# CY8C5888LTI_LP097 register map
File version: 0.1
CY8C58LP
Registers are 8-bit, read-write, no defined reset value unless marked. A register's access mark holds for its fields unless they carry their own. Offsets are from the block's base; lines under a group give offsets from that group; [hi:lo] are bit positions; {n}, {i} and the like mark numbered series; 'fields as' and 'values as' point back to an identical list; <NAME> marks a mode.

## Memory map
0x00000000 SLM_TRIG
0x00000000 BLANKING_DELAY
0x00000000 CAM_SEL_REG
0x00000000 ACTIVATE_SLM
0x00000000 BLANK_TOGGLE
0x00000000 TRIG_CNT_RST
0x00000000 USBUART — USBFS
0x00000000 TRG_CNT
0x00000000 STAGE_REG
0x00000000 STAGE_TRIG
0x00000000 SLM_WAIT
0x00000000 ENBL_TRIG_ISR

## SLM_TRIG
Base 0x00000000
0x40006408 SLM_TRIG_COUNTER 32-bit — UDB.A0 - Current Counter Value
0x40006428 SLM_TRIG_PERIOD 32-bit — UDB.D0 - Assigned Period
0x40006438 SLM_TRIG_COMPARE 32-bit — UDB.D1 - Assigned Compare Value
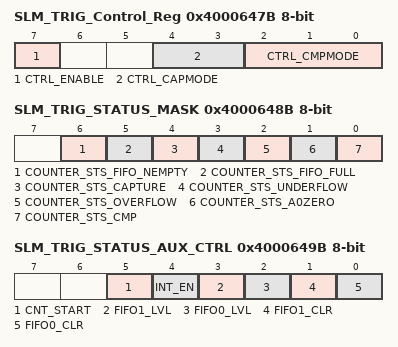
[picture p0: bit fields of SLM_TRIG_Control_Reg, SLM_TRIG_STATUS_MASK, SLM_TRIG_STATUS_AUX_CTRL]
0x4000647B SLM_TRIG_Control_Reg — UDB Control Register - Assigned Control Register Value
  [7] CTRL_ENABLE — Enable Counter
  [4:3] CTRL_CAPMODE — Capture mode
  [2:0] CTRL_CMPMODE — Compare mode
0x4000648B SLM_TRIG_STATUS_MASK — UDB Status bits Interrupt Mask Enable Register
  [6] COUNTER_STS_FIFO_NEMPTY — FIFO Not Empty Status
  [5] COUNTER_STS_FIFO_FULL — FIFO Full Status
  [4] COUNTER_STS_CAPTURE — Capture Status
  [3] COUNTER_STS_UNDERFLOW — Underflow status
  [2] COUNTER_STS_OVERFLOW — Overflow status
  [1] COUNTER_STS_A0ZERO — A0 Zero ouput status
  [0] COUNTER_STS_CMP — Compare output status
0x4000649B SLM_TRIG_STATUS_AUX_CTRL — UDB Auxilliary Control Register
  [5] CNT_START — FIFO0 clear
    0=E_CNT_START0 (Disable counter); 1=E_CNT_START1 (Enable counter)
  [4] INT_EN
    0=E_INT_EN0 (Interrupt disabled); 1=E_INT_EN1 (Interrupt enabled)
  [3] FIFO1_LVL — FIFO level
    0=E_FIFO_LVL_0 (FIFO LVL: input mode: FIFO not full; output mode: FIFO not empty); 1=E_FIFO_LVL_1 (FIFO LVL: input mode: FIFO at least 1/2 empty; output mode: FIFO at least 1/2 full)
  [2] FIFO0_LVL — FIFO level
    values as FIFO1_LVL
  [1] FIFO1_CLR — FIFO1 clear
    0=E_FIFO_CLR_0 (Normal FIFO operation); 1=E_FIFO_CLR_1 (Clear FIFO state)
  [0] FIFO0_CLR — FIFO0 clear
    values as FIFO1_CLR

## BLANKING_DELAY
Base 0x00000000
0x40006402 BLANKING_DELAY_COUNTER 32-bit — UDB.A0 - Current Counter Value
0x40006422 BLANKING_DELAY_PERIOD 32-bit — UDB.D0 - Assigned Period
0x40006432 BLANKING_DELAY_COMPARE 32-bit — UDB.D1 - Assigned Compare Value
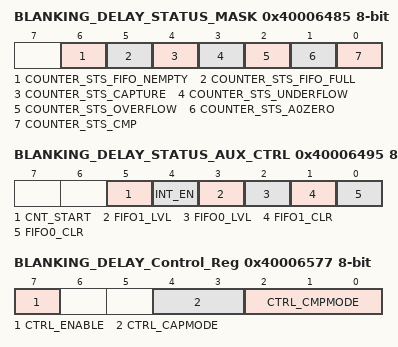
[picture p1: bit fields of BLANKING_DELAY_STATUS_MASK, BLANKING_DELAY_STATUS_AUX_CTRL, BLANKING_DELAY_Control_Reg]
0x40006485 BLANKING_DELAY_STATUS_MASK — UDB Status bits Interrupt Mask Enable Register
  [6] COUNTER_STS_FIFO_NEMPTY — FIFO Not Empty Status
  [5] COUNTER_STS_FIFO_FULL — FIFO Full Status
  [4] COUNTER_STS_CAPTURE — Capture Status
  [3] COUNTER_STS_UNDERFLOW — Underflow status
  [2] COUNTER_STS_OVERFLOW — Overflow status
  [1] COUNTER_STS_A0ZERO — A0 Zero ouput status
  [0] COUNTER_STS_CMP — Compare output status
0x40006495 BLANKING_DELAY_STATUS_AUX_CTRL — UDB Auxilliary Control Register
  [5] CNT_START — FIFO0 clear
    0=E_CNT_START0 (Disable counter); 1=E_CNT_START1 (Enable counter)
  [4] INT_EN
    0=E_INT_EN0 (Interrupt disabled); 1=E_INT_EN1 (Interrupt enabled)
  [3] FIFO1_LVL — FIFO level
    0=E_FIFO_LVL_0 (FIFO LVL: input mode: FIFO not full; output mode: FIFO not empty); 1=E_FIFO_LVL_1 (FIFO LVL: input mode: FIFO at least 1/2 empty; output mode: FIFO at least 1/2 full)
  [2] FIFO0_LVL — FIFO level
    values as FIFO1_LVL
  [1] FIFO1_CLR — FIFO1 clear
    0=E_FIFO_CLR_0 (Normal FIFO operation); 1=E_FIFO_CLR_1 (Clear FIFO state)
  [0] FIFO0_CLR — FIFO0 clear
    values as FIFO1_CLR
0x40006577 BLANKING_DELAY_Control_Reg — UDB Control Register - Assigned Control Register Value
  [7] CTRL_ENABLE — Enable Counter
  [4:3] CTRL_CAPMODE — Capture mode
  [2:0] CTRL_CMPMODE — Compare mode

## CAM_SEL_REG
Base 0x00000000
0x40006576 CAM_SEL_REG_CONTROL_REG

## ACTIVATE_SLM
Base 0x00000000
0x4000647F ACTIVATE_SLM_CONTROL_REG
